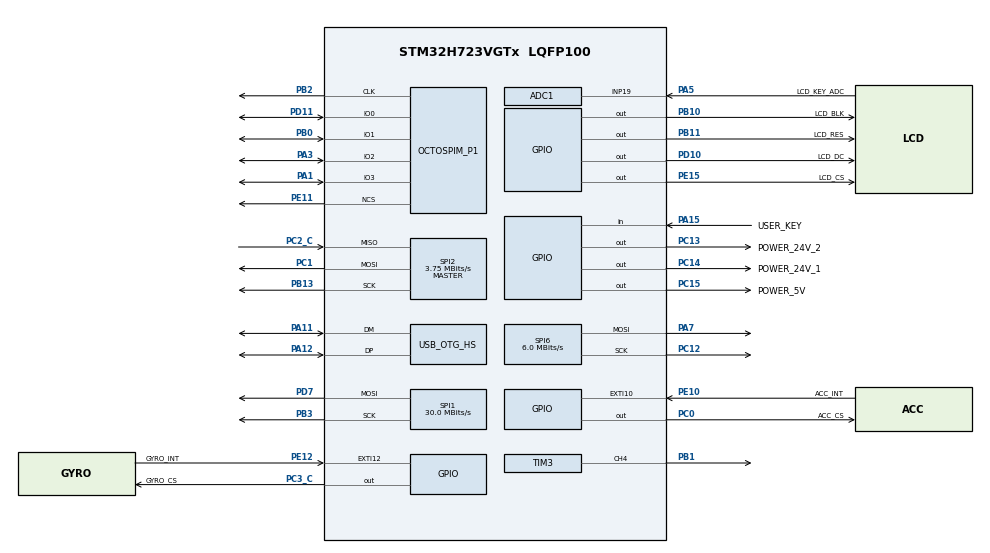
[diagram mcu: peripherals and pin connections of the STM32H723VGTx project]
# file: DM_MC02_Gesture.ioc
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ADC1.Channel-0\#ChannelRegularConversion=ADC_CHANNEL_19
ADC1.ClockPrescaler=ADC_CLOCK_ASYNC_DIV64
ADC1.ContinuousConvMode=DISABLE
ADC1.ConversionDataManagement=ADC_CONVERSIONDATA_DR
ADC1.EOCSelection=ADC_EOC_SINGLE_CONV
ADC1.NbrOfConversionFlag=1
ADC1.OffsetNumber-0\#ChannelRegularConversion=ADC_OFFSET_NONE
ADC1.OffsetSignedSaturation-0\#ChannelRegularConversion=DISABLE
ADC1.Rank-0\#ChannelRegularConversion=1
ADC1.Resolution=ADC_RESOLUTION_16B
ADC1.SamplingTime-0\#ChannelRegularConversion=ADC_SAMPLETIME_64CYCLES_5
ADC1.master=1
CORTEX_M7.CPU_DCache=Disabled
CORTEX_M7.CPU_ICache=Enabled
Dma.Request0=SPI2_RX
Dma.Request1=SPI2_TX
Dma.Request2=SPI1_TX
Dma.SPI1_TX.2.Direction=DMA_MEMORY_TO_PERIPH
Dma.SPI1_TX.2.EventEnable=DISABLE
Dma.SPI1_TX.2.FIFOMode=DMA_FIFOMODE_DISABLE
Dma.SPI1_TX.2.Instance=DMA1_Stream2
Dma.SPI1_TX.2.MemDataAlignment=DMA_MDATAALIGN_BYTE
Dma.SPI1_TX.2.MemInc=DMA_MINC_ENABLE
Dma.SPI1_TX.2.Mode=DMA_NORMAL
Dma.SPI1_TX.2.PeriphDataAlignment=DMA_PDATAALIGN_BYTE
Dma.SPI1_TX.2.PeriphInc=DMA_PINC_DISABLE
Dma.SPI1_TX.2.Polarity=HAL_DMAMUX_REQ_GEN_RISING
Dma.SPI1_TX.2.Priority=DMA_PRIORITY_LOW
Dma.SPI1_TX.2.RequestNumber=1
Dma.SPI1_TX.2.SignalID=NONE
Dma.SPI1_TX.2.SyncEnable=DISABLE
Dma.SPI1_TX.2.SyncPolarity=HAL_DMAMUX_SYNC_NO_EVENT
Dma.SPI1_TX.2.SyncRequestNumber=1
Dma.SPI1_TX.2.SyncSignalID=NONE
Dma.SPI2_RX.0.Direction=DMA_PERIPH_TO_MEMORY
Dma.SPI2_RX.0.EventEnable=DISABLE
Dma.SPI2_RX.0.FIFOMode=DMA_FIFOMODE_DISABLE
Dma.SPI2_RX.0.Instance=DMA1_Stream0
Dma.SPI2_RX.0.MemDataAlignment=DMA_MDATAALIGN_BYTE
Dma.SPI2_RX.0.MemInc=DMA_MINC_ENABLE
Dma.SPI2_RX.0.Mode=DMA_NORMAL
Dma.SPI2_RX.0.PeriphDataAlignment=DMA_PDATAALIGN_BYTE
Dma.SPI2_RX.0.PeriphInc=DMA_PINC_DISABLE
Dma.SPI2_RX.0.Polarity=HAL_DMAMUX_REQ_GEN_RISING
Dma.SPI2_RX.0.Priority=DMA_PRIORITY_VERY_HIGH
Dma.SPI2_RX.0.RequestNumber=1
Dma.SPI2_RX.0.SignalID=NONE
Dma.SPI2_RX.0.SyncEnable=DISABLE
Dma.SPI2_RX.0.SyncPolarity=HAL_DMAMUX_SYNC_NO_EVENT
Dma.SPI2_RX.0.SyncRequestNumber=1
Dma.SPI2_RX.0.SyncSignalID=NONE
Dma.SPI2_TX.1.Direction=DMA_MEMORY_TO_PERIPH
Dma.SPI2_TX.1.EventEnable=DISABLE
Dma.SPI2_TX.1.FIFOMode=DMA_FIFOMODE_DISABLE
Dma.SPI2_TX.1.Instance=DMA1_Stream1
Dma.SPI2_TX.1.MemDataAlignment=DMA_MDATAALIGN_BYTE
Dma.SPI2_TX.1.MemInc=DMA_MINC_ENABLE
Dma.SPI2_TX.1.Mode=DMA_NORMAL
Dma.SPI2_TX.1.PeriphDataAlignment=DMA_PDATAALIGN_BYTE
Dma.SPI2_TX.1.PeriphInc=DMA_PINC_DISABLE
Dma.SPI2_TX.1.Polarity=HAL_DMAMUX_REQ_GEN_RISING
Dma.SPI2_TX.1.Priority=DMA_PRIORITY_HIGH
Dma.SPI2_TX.1.RequestNumber=1
Dma.SPI2_TX.1.SignalID=NONE
Dma.SPI2_TX.1.SyncEnable=DISABLE
Dma.SPI2_TX.1.SyncPolarity=HAL_DMAMUX_SYNC_NO_EVENT
Dma.SPI2_TX.1.SyncRequestNumber=1
Dma.SPI2_TX.1.SyncSignalID=NONE
Mcu.Family=STM32H7
Mcu.Name=STM32H723VGTx
Mcu.Package=LQFP100
NVIC.DMA1_Stream0_IRQn=true\:2\:0\:true\:false\:true\:false\:true\:true
NVIC.DMA1_Stream1_IRQn=true\:2\:0\:true\:false\:true\:false\:true\:true
NVIC.DMA1_Stream2_IRQn=true\:7\:0\:true\:false\:true\:false\:true\:true
NVIC.EXTI15_10_IRQn=true\:3\:0\:true\:false\:true\:false\:true\:true
NVIC.OTG_HS_IRQn=true\:6\:0\:true\:false\:true\:false\:true\:true
NVIC.PriorityGroup=NVIC_PRIORITYGROUP_4
NVIC.SPI1_IRQn=true\:7\:0\:true\:false\:true\:false\:true\:true
NVIC.SPI2_IRQn=true\:2\:0\:true\:false\:true\:false\:true\:true
NVIC.TIM7_IRQn=true\:4\:0\:true\:false\:true\:false\:true\:true
OCTOSPI2.ChipSelectHighTime=4
OCTOSPI2.ClockMode=HAL_OSPI_CLOCK_MODE_3
OCTOSPI2.ClockPrescaler=8
OCTOSPI2.DeviceSize=23
OCTOSPI2.DeviceType=SPI_DEVICE_FLASH
OCTOSPI2.FifoThreshold=8
OCTOSPI2.SampleShifting=HAL_OSPI_SAMPLE_SHIFTING_HALFCYCLE
PA1.GPIO_Speed=GPIO_SPEED_FREQ_VERY_HIGH
PA1.Mode=OCTOSPI2_IOL_Port1L
PA1.Signal=OCTOSPIM_P1_IO3
PA11.Mode=Device_Only_FS
PA11.Signal=USB_OTG_HS_DM
PA12.Mode=Device_Only_FS
PA12.Signal=USB_OTG_HS_DP
PA13(JTMS/SWDIO).Mode=Serial_Wire
PA13(JTMS/SWDIO).Signal=DEBUG_JTMS-SWDIO
PA14(JTCK/SWCLK).Mode=Serial_Wire
PA14(JTCK/SWCLK).Signal=DEBUG_JTCK-SWCLK
PA15(JTDI).GPIO_Label=USER_KEY
PA15(JTDI).GPIO_PuPd=GPIO_PULLUP
PA15(JTDI).Signal=GPIO_Input
PA3.GPIO_Speed=GPIO_SPEED_FREQ_VERY_HIGH
PA3.Mode=OCTOSPI2_IOL_Port1L
PA3.Signal=OCTOSPIM_P1_IO2
PA5.GPIO_Label=LCD_KEY_ADC
PA5.Signal=ADCx_INP19
PA7.GPIO_Speed=GPIO_SPEED_FREQ_VERY_HIGH
PA7.Mode=TX_Only_Simplex_Unidirect_Master
PA7.Signal=SPI6_MOSI
PB0.GPIO_Speed=GPIO_SPEED_FREQ_VERY_HIGH
PB0.Mode=OCTOSPI2_IOL_Port1L
PB0.Signal=OCTOSPIM_P1_IO1
PB1.Signal=S_TIM3_CH4
PB10.GPIO_Label=LCD_BLK
PB10.PinState=GPIO_PIN_RESET
PB10.Signal=GPIO_Output
PB11.GPIO_Label=LCD_RES
PB11.PinState=GPIO_PIN_RESET
PB11.Signal=GPIO_Output
PB13.GPIO_Speed=GPIO_SPEED_FREQ_VERY_HIGH
PB13.Mode=Full_Duplex_Master
PB13.Signal=SPI2_SCK
PB2.GPIO_Speed=GPIO_SPEED_FREQ_VERY_HIGH
PB2.Mode=O2_P1_CLK
PB2.Signal=OCTOSPIM_P1_CLK
PB3(JTDO/TRACESWO).GPIO_Speed=GPIO_SPEED_FREQ_VERY_HIGH
PB3(JTDO/TRACESWO).Mode=TX_Only_Simplex_Unidirect_Master
PB3(JTDO/TRACESWO).Signal=SPI1_SCK
PC0.GPIO_Label=ACC_CS
PC0.GPIO_Speed=GPIO_SPEED_FREQ_VERY_HIGH
PC0.PinState=GPIO_PIN_SET
PC0.Signal=GPIO_Output
PC1.GPIO_Speed=GPIO_SPEED_FREQ_VERY_HIGH
PC1.Mode=Full_Duplex_Master
PC1.Signal=SPI2_MOSI
PC12.GPIO_Speed=GPIO_SPEED_FREQ_VERY_HIGH
PC12.Mode=TX_Only_Simplex_Unidirect_Master
PC12.Signal=SPI6_SCK
PC13.GPIO_Label=POWER_24V_2
PC13.PinState=GPIO_PIN_RESET
PC13.Signal=GPIO_Output
PC14-OSC32_IN.GPIO_Label=POWER_24V_1
PC14-OSC32_IN.PinState=GPIO_PIN_RESET
PC14-OSC32_IN.Signal=GPIO_Output
PC15-OSC32_OUT.GPIO_Label=POWER_5V
PC15-OSC32_OUT.PinState=GPIO_PIN_RESET
PC15-OSC32_OUT.Signal=GPIO_Output
PC2_C.GPIO_Speed=GPIO_SPEED_FREQ_VERY_HIGH
PC2_C.Mode=Full_Duplex_Master
PC2_C.Signal=SPI2_MISO
PC3_C.GPIO_Label=GYRO_CS
PC3_C.GPIO_Speed=GPIO_SPEED_FREQ_VERY_HIGH
PC3_C.PinState=GPIO_PIN_SET
PC3_C.Signal=GPIO_Output
PD10.GPIO_Label=LCD_DC
PD10.GPIO_Speed=GPIO_SPEED_FREQ_VERY_HIGH
PD10.Signal=GPIO_Output
PD11.GPIO_Speed=GPIO_SPEED_FREQ_VERY_HIGH
PD11.Mode=OCTOSPI2_IOL_Port1L
PD11.Signal=OCTOSPIM_P1_IO0
PD7.GPIO_Speed=GPIO_SPEED_FREQ_VERY_HIGH
PD7.Mode=TX_Only_Simplex_Unidirect_Master
PD7.Signal=SPI1_MOSI
PE10.GPIO_Label=ACC_INT
PE10.GPIO_ModeDefaultEXTI=GPIO_MODE_IT_FALLING
PE10.Signal=GPXTI10
PE11.GPIO_Speed=GPIO_SPEED_FREQ_VERY_HIGH
PE11.Mode=OCTOSPI2_Port1_NCS
PE11.Signal=OCTOSPIM_P1_NCS
PE12.GPIO_Label=GYRO_INT
PE12.GPIO_ModeDefaultEXTI=GPIO_MODE_IT_FALLING
PE12.Signal=GPXTI12
PE15.GPIO_Label=LCD_CS
PE15.GPIO_Speed=GPIO_SPEED_FREQ_VERY_HIGH
PE15.PinState=GPIO_PIN_SET
PE15.Signal=GPIO_Output
PH0-OSC_IN.Mode=HSE-External-Oscillator
PH0-OSC_IN.Signal=RCC_OSC_IN
PH1-OSC_OUT.Mode=HSE-External-Oscillator
PH1-OSC_OUT.Signal=RCC_OSC_OUT
ProjectManager.HeapSize=0x400
ProjectManager.StackSize=0x4000
ProjectManager.TargetToolchain=MDK-ARM V5.32
RCC.ADCFreq_Value=96000000
RCC.APB1Freq_Value=120000000
RCC.APB2Freq_Value=120000000
RCC.APB3Freq_Value=120000000
RCC.APB4Freq_Value=120000000
RCC.CortexFreq_Value=480000000
RCC.D1PPRE=RCC_APB3_DIV2
RCC.D2PPRE1=RCC_APB1_DIV2
RCC.D2PPRE2=RCC_APB2_DIV2
RCC.D3PPRE=RCC_APB4_DIV2
RCC.DIVM1=2
RCC.DIVM2=2
RCC.DIVN1=40
RCC.DIVN2=16
RCC.DIVP1=1
RCC.DIVQ1=4
RCC.HCLKFreq_Value=240000000
RCC.HPRE=RCC_HCLK_DIV2
RCC.HSE_VALUE=24000000
RCC.PLL2FRACN=0
RCC.PLL3FRACN=0
RCC.PLLFRACN=0
RCC.PLLSourceVirtual=RCC_PLLSOURCE_HSE
RCC.SPI6CLockSelection=RCC_SPI6CLKSOURCE_HSE
RCC.SYSCLKFreq_VALUE=480000000
RCC.SYSCLKSource=RCC_SYSCLKSOURCE_PLLCLK
RCC.USBCLockSelection=RCC_USBCLKSOURCE_HSI48
RCC.USBFreq_Value=48000000
SH.ADCx_INP19.0=ADC1_INP19,IN19-Single-Ended
SH.S_TIM3_CH4.0=TIM3_CH4,PWM Generation4 CH4
SPI1.BaudRatePrescaler=SPI_BAUDRATEPRESCALER_4
SPI1.CLKPhase=SPI_PHASE_1EDGE
SPI1.CLKPolarity=SPI_POLARITY_HIGH
SPI1.CalculateBaudRate=30.0 MBits/s
SPI1.DataSize=SPI_DATASIZE_8BIT
SPI1.Direction=SPI_DIRECTION_2LINES_TXONLY
SPI1.Mode=SPI_MODE_MASTER
SPI1.VirtualType=VM_MASTER
SPI2.BaudRatePrescaler=SPI_BAUDRATEPRESCALER_32
SPI2.CLKPhase=SPI_PHASE_2EDGE
SPI2.CLKPolarity=SPI_POLARITY_HIGH
SPI2.CalculateBaudRate=3.75 MBits/s
SPI2.DataSize=SPI_DATASIZE_8BIT
SPI2.Direction=SPI_DIRECTION_2LINES
SPI2.Mode=SPI_MODE_MASTER
SPI2.VirtualType=VM_MASTER
SPI6.BaudRatePrescaler=SPI_BAUDRATEPRESCALER_4
SPI6.CLKPhase=SPI_PHASE_2EDGE
SPI6.CLKPolarity=SPI_POLARITY_LOW
SPI6.CalculateBaudRate=6.0 MBits/s
SPI6.DataSize=SPI_DATASIZE_8BIT
SPI6.Direction=SPI_DIRECTION_2LINES_TXONLY
SPI6.Mode=SPI_MODE_MASTER
SPI6.VirtualType=VM_MASTER
TIM3.AutoReloadPreload=TIM_AUTORELOAD_PRELOAD_ENABLE
TIM3.Channel-PWM\ Generation4\ CH4=TIM_CHANNEL_4
TIM3.Period=9999
TIM3.Prescaler=23
TIM3.Pulse-PWM\ Generation4\ CH4=0
TIM7.Period=4999
TIM7.Prescaler=239
USB_DEVICE.CLASS_NAME_HS=CDC
USB_DEVICE.VirtualMode=Cdc
USB_DEVICE.VirtualModeHS=Cdc_HS
USB_OTG_HS.VirtualMode-Device_Only_FS=Device_Only_FS
VP_OCTOSPI2_VS_quad.Mode=quad_mode
VP_TIM7_VS_ClockSourceINT.Mode=Enable_Timer
VP_USB_DEVICE_VS_USB_DEVICE_CDC_HS.Mode=CDC_HS
board=custom

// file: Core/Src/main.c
/* USER CODE BEGIN Header */
/**
  ******************************************************************************
  * @file           : main.c
  * @brief          : Main program body
  ******************************************************************************
  * @attention
  *
  * Copyright (c) 2026 STMicroelectronics.
  * All rights reserved.
  *
  * This software is licensed under terms that can be found in the LICENSE file
  * in the root directory of this software component.
  * If no LICENSE file comes with this software, it is provided AS-IS.
  *
  ******************************************************************************
  */
/* USER CODE END Header */
#include "main.h"
#include "adc.h"
#include "dma.h"
#include "octospi.h"
#include "spi.h"
#include "tim.h"
#include "usb_device.h"
#include "gpio.h"

/* USER CODE BEGIN Includes */
#include "gesture_app.h"
/* USER CODE END Includes */

void SystemClock_Config(void);

int main(void)
{

  /* Enable the CPU Cache */

  /* Enable I-Cache---------------------------------------------------------*/
  SCB_EnableICache();

  /* MCU Configuration--------------------------------------------------------*/

  /* Reset of all peripherals, Initializes the Flash interface and the Systick. */
  HAL_Init();

  /* Configure the system clock */
  SystemClock_Config();

  /* Initialize all configured peripherals */
  MX_GPIO_Init();
  MX_DMA_Init();
  MX_ADC1_Init();
  MX_SPI2_Init();
  MX_SPI1_Init();
  MX_SPI6_Init();
  MX_OCTOSPI2_Init();
  MX_TIM3_Init();
  MX_TIM7_Init();
  MX_USB_DEVICE_Init();
  /* USER CODE BEGIN 2 */
  gesture_app_init();
  /* USER CODE END 2 */

  /* Infinite loop */
  while (1)
  {

    /* USER CODE BEGIN 3 */
    gesture_app_process();
  }
  /* USER CODE END 3 */
}

void SystemClock_Config(void)
{
  RCC_OscInitTypeDef RCC_OscInitStruct = {0};
  RCC_ClkInitTypeDef RCC_ClkInitStruct = {0};

  /** Supply configuration update enable
  */
  HAL_PWREx_ConfigSupply(PWR_LDO_SUPPLY);

  /** Configure the main internal regulator output voltage
  */
  __HAL_PWR_VOLTAGESCALING_CONFIG(PWR_REGULATOR_VOLTAGE_SCALE0);

  while(!__HAL_PWR_GET_FLAG(PWR_FLAG_VOSRDY)) {}

  /** Initializes the RCC Oscillators according to the specified parameters
  * in the RCC_OscInitTypeDef structure.
  */
  RCC_OscInitStruct.OscillatorType = RCC_OSCILLATORTYPE_HSI48|RCC_OSCILLATORTYPE_HSE;
  RCC_OscInitStruct.HSEState = RCC_HSE_ON;
  RCC_OscInitStruct.HSI48State = RCC_HSI48_ON;
  RCC_OscInitStruct.PLL.PLLState = RCC_PLL_ON;
  RCC_OscInitStruct.PLL.PLLSource = RCC_PLLSOURCE_HSE;
  RCC_OscInitStruct.PLL.PLLM = 2;
  RCC_OscInitStruct.PLL.PLLN = 40;
  RCC_OscInitStruct.PLL.PLLP = 1;
  RCC_OscInitStruct.PLL.PLLQ = 4;
  RCC_OscInitStruct.PLL.PLLR = 2;
  RCC_OscInitStruct.PLL.PLLRGE = RCC_PLL1VCIRANGE_3;
  RCC_OscInitStruct.PLL.PLLVCOSEL = RCC_PLL1VCOWIDE;
  RCC_OscInitStruct.PLL.PLLFRACN = 0;
  if (HAL_RCC_OscConfig(&RCC_OscInitStruct) != HAL_OK)
  {
    Error_Handler();
  }

  /** Initializes the CPU, AHB and APB buses clocks
  */
  RCC_ClkInitStruct.ClockType = RCC_CLOCKTYPE_HCLK|RCC_CLOCKTYPE_SYSCLK
                              |RCC_CLOCKTYPE_PCLK1|RCC_CLOCKTYPE_PCLK2
                              |RCC_CLOCKTYPE_D3PCLK1|RCC_CLOCKTYPE_D1PCLK1;
  RCC_ClkInitStruct.SYSCLKSource = RCC_SYSCLKSOURCE_PLLCLK;
  RCC_ClkInitStruct.SYSCLKDivider = RCC_SYSCLK_DIV1;
  RCC_ClkInitStruct.AHBCLKDivider = RCC_HCLK_DIV2;
  RCC_ClkInitStruct.APB3CLKDivider = RCC_APB3_DIV2;
  RCC_ClkInitStruct.APB1CLKDivider = RCC_APB1_DIV2;
  RCC_ClkInitStruct.APB2CLKDivider = RCC_APB2_DIV2;
  RCC_ClkInitStruct.APB4CLKDivider = RCC_APB4_DIV2;

  if (HAL_RCC_ClockConfig(&RCC_ClkInitStruct, FLASH_LATENCY_3) != HAL_OK)
  {
    Error_Handler();
  }
}

/* USER CODE BEGIN 4 */
void HAL_TIM_PeriodElapsedCallback(TIM_HandleTypeDef *htim)
{
  if (htim->Instance == TIM7) gesture_app_tick_isr();
}
/* USER CODE END 4 */

void Error_Handler(void)
{
  __disable_irq();
  while (1)
  {
  }
}
